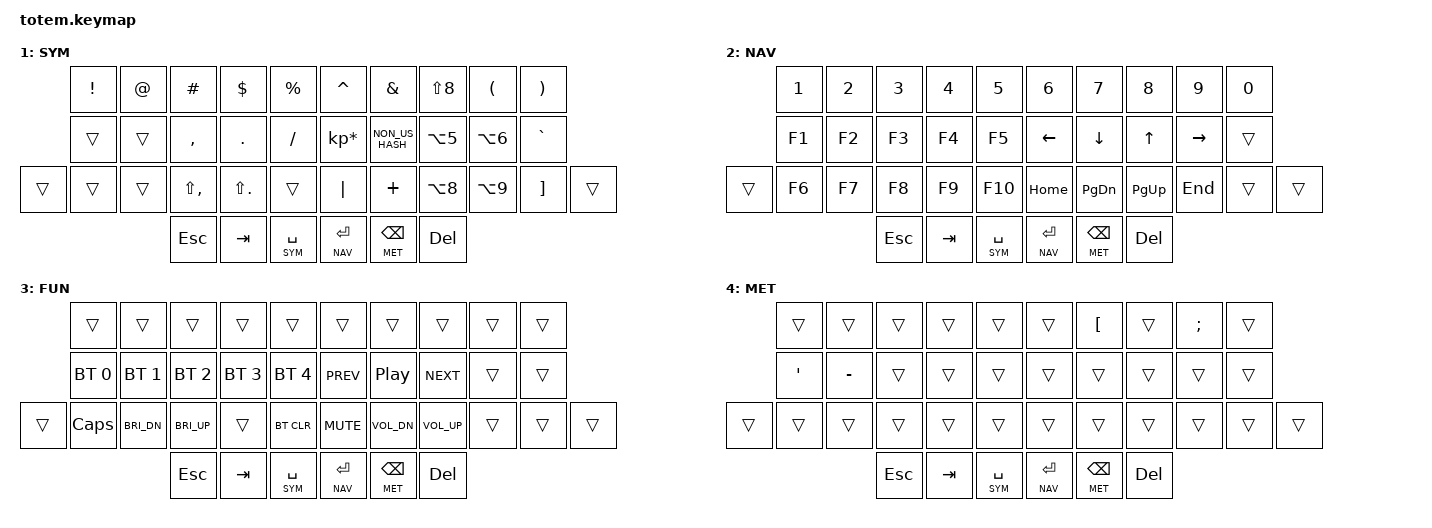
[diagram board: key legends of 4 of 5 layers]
//
//                                                        ▀▀▀▀▀     ▀▀▀▀▀          ▀▀█▀▀
//                                                        ▄▀▀▀▄  ▄  ▄▀▀▀▄  ▄  ▄▀▀▀▄  █  ▄▀▀▀▄
//                                                        █   █  █  █   █  █  █   █  █  █   █
//                                                         ▀▀▀   █   ▀▀▀   █   ▀▀▀   ▀   ▀▀▀
//                                                               █      ▄▄▄█▄▄▄    █   █  
//                                                               ▀      █  █  █     █▄█
//                                                             ▀▀▀▀▀    █  █  █      ▀
//                                                                      ▀  ▀  ▀
//
// ▄▄▄▄▄▄▄▄▄▄▄▄▄▄▄▄▄▄▄▄▄▄▄▄▄▄▄▄▄▄▄▄▄▄▄▄▄▄▄▄▄▄▄▄▄▄▄▄▄▄▄▄▄▄▄▄▄▄▄▄▄▄▄▄▄▄▄▄▄▄▄▄▄▄▄▄▄▄▄▄▄▄▄▄▄▄▄▄▄▄▄▄▄▄▄▄▄▄▄▄▄▄▄▄▄▄▄▄▄▄▄▄▄▄▄▄▄▄▄▄▄▄▄▄▄▄▄▄▄▄▄▄▄▄▄▄▄▄▄▄▄▄▄▄▄▄▄▄▄
       

#include <behaviors.dtsi>
#include <dt-bindings/zmk/keys.h>
#include <dt-bindings/zmk/bt.h>
#include <dt-bindings/zmk/outputs.h>

#define DEF 0
#define SYM 1
#define NAV 2
#define FUN 3
#define MET 4

//&mt {
//  quick-tap-ms = <100>;
//  global-quick-tap;
//  flavor = "tap-preferred";
//  tapping-term-ms = <170>;
//};
&mt {
    flavor = "hold-preferred";
    tapping-term-ms = <150>;
};

&lt {
    flavor = "balanced";
    tapping-term-ms = <150>;
};

/ {
    behaviors {
        am: alpha_mods {
            compatible = "zmk,behavior-hold-tap";
            label = "ALPHA_MT";
            #binding-cells = <2>;
            tapping-term-ms = <200>;
            quick-tap-ms = <150>;
            flavor = "balanced";
            bindings = <&kp>, <&kp>;
        };
        as: alpha_shift {
            compatible = "zmk,behavior-hold-tap";
            label = "ALPHA_SFT";
            #binding-cells = <2>;
            tapping-term-ms = <200>;
            quick-tap-ms = <150>;
            flavor = "balanced";
            bindings = <&kp>, <&kp>;
        };

        // Easy alt-tab with alt+backspace thumb using mod-morphs
        bstab: backspace_tab {
            compatible = "zmk,behavior-mod-morph";
            label = "BSPC_TAB";
            #binding-cells = <0>;
            bindings = <&kp BSPC>, <&kp TAB>;
            mods = <MOD_LALT>;
        };
        lt_bspc: layer_tap_backspace_tab {
            compatible = "zmk,behavior-hold-tap";
            label = "LT_BT";
            #binding-cells = <2>;
            tapping-term-ms = <150>;
            flavor = "balanced";
            bindings = <&mo>, <&bstab>;
        };
    };

    cond_layers {
        compatible = "zmk,conditional-layers";
        // Define FUN layer as tri-state
        func_tristate {
            if-layers = <NAV SYM>;
            then-layer = <FUN>;
        };
    };

    macros {
        ZMK_MACRO(inv_qm,
            wait-ms = <10>;
            tap-ms = <10>;
            bindings
                = <&macro_press &kp LALT>
                , <&macro_tap &kp KP_N1 &kp KP_N6 &kp KP_N8>
                , <&macro_release &kp LALT>;
        )
    };

        keymap {
                compatible = "zmk,keymap";
// ▄▄▄▄▄▄▄▄▄▄▄▄▄▄▄▄▄▄▄▄▄▄▄▄▄▄▄▄▄▄▄▄▄▄▄▄▄▄▄▄▄▄▄▄▄▄▄▄▄▄▄▄▄▄▄▄▄▄▄▄▄▄▄▄▄▄▄▄▄▄▄▄▄▄▄▄▄▄▄▄▄▄▄▄▄▄▄▄▄▄▄▄▄▄▄▄▄▄▄▄▄▄▄▄▄▄▄▄▄▄▄▄▄▄▄▄▄▄▄▄▄▄▄▄▄▄▄▄▄▄▄▄▄▄▄▄▄▄▄▄▄▄▄▄▄▄▄▄▄

                base_layer {
// ┏━━━━━━━━━━━━━━━━━━━━━━━━━━━━━━━━━━━━━━━┓
label= "BASE"                              ;
// ┗━━━━━━━━━━━━━━━━━━━━━━━━━━━━━━━━━━━━━━━┛
//             ┏━━━━━━━━━━━┳━━━━━━━━━━━┳━━━━━━━━━━━┳━━━━━━━━━━━┳━━━━━━━━━━━┓   ┏━━━━━━━━━━━┳━━━━━━━━━━━┳━━━━━━━━━━━┳━━━━━━━━━━━┳━━━━━━━━━━━┓
//             ┃     Q     ┃     W     ┃     F     ┃     P     ┃     G     ┃   ┃     J     ┃     L     ┃     U     ┃     Y     ┃     ;     ┃
//             ┣━━━━━━━━━━━╋━━━━━━━━━━━╋━━━━━━━━━━━╋━━━━━━━━━━━╋━━━━━━━━━━━┫   ┣━━━━━━━━━━━╋━━━━━━━━━━━╋━━━━━━━━━━━╋━━━━━━━━━━━╋━━━━━━━━━━━┫
//             ┃     A     ┃     R     ┃     S     ┃     T     ┃     D     ┃   ┃     H     ┃     N     ┃     E     ┃     I     ┃     O     ┃
// ┏━━━━━━━━━━━╋━━━━━━━━━━━╋━━━━━━━━━━━╋━━━━━━━━━━━╋━━━━━━━━━━━╋━━━━━━━━━━━┫   ┣━━━━━━━━━━━╋━━━━━━━━━━━╋━━━━━━━━━━━╋━━━━━━━━━━━╋━━━━━━━━━━━╋━━━━━━━━━━━┓
// ┃     Q     ┃     Z     ┃     X     ┃     C     ┃     V     ┃     B     ┃   ┃     K     ┃     M     ┃     ,     ┃     .     ┃     /     ┃     \     ┃
// ┗━━━━━━━━━━━┻━━━━━━━━━━━┻━━━━━━━━━━━╋━━━━━━━━━━━╋━━━━━━━━━━━╋━━━━━━━━━━━┫   ┣━━━━━━━━━━━╋━━━━━━━━━━━╋━━━━━━━━━━━╋━━━━━━━━━━━┻━━━━━━━━━━━┻━━━━━━━━━━━┛
//                                     ┃    DEL    ┃    TAB    ┃    SPC    ┃   ┃   ENTER   ┃           ┃   BSPC    ┃
//                                     ┗━━━━━━━━━━━┻━━━━━━━━━━━┻━━━━━━━━━━━┛   ┗━━━━━━━━━━━┻━━━━━━━━━━━┻━━━━━━━━━━━┛
 bindings = <
// ╷           ╷           ╷           ╷           ╷           ╷           ╷   ╷           ╷           ╷           ╷           ╷           ╷           ╷
//                &kp Q       &kp W       &kp F       &kp P       &kp G           &kp J       &kp L       &kp U       &kp Y       &kp SEMI
//                &mt LGUI A  &mt LALT R  &mt LCTRL S &mt LSHFT T &kp D           &kp H       &mt RSHFT N &mt RCTRL E &mt RALT I  &mt RGUI O
//    &kp Q       &kp Z       &kp X       &kp C       &kp V       &kp B           &kp K       &kp M       &kp COMMA   &kp DOT     &kp FSLH    &kp BSLH
//                                        &kp DEL   &lt NAV TAB   &kp SPACE       &kp RET   &lt SYM ESC   &kp BSPC
                &kp Q       &kp W       &kp E       &kp R       &kp T           &kp Y       &kp U       &kp I       &kp O       &kp P
                &am LCTRL A   &am LGUI S    &am LALT D    &as LSHFT F   &kp G             &kp H         &as RSHFT J   &am RALT K   &am RGUI L    &am RCTRL SEMI
    &kp Q       &kp Z       &kp X       &kp C       &kp V       &kp B           &kp N       &kp M       &kp COMMA   &kp DOT     &kp FSLH    &kp BSLH
                                        &kp ESC       &kp TAB       &lt SYM SPACE &lt NAV RET   &lt MET BSPC  &kp DEL
                                        
     &kp SQT        &kp LBKT       &kp SEMI                                           
                        >;
                };

// ▄▄▄▄▄▄▄▄▄▄▄▄▄▄▄▄▄▄▄▄▄▄▄▄▄▄▄▄▄▄▄▄▄▄▄▄▄▄▄▄▄▄▄▄▄▄▄▄▄▄▄▄▄▄▄▄▄▄▄▄▄▄▄▄▄▄▄▄▄▄▄▄▄▄▄▄▄▄▄▄▄▄▄▄▄▄▄▄▄▄▄▄▄▄▄▄▄▄▄▄▄▄▄▄▄▄▄▄▄▄▄▄▄▄▄▄▄▄▄▄▄▄▄▄▄▄▄▄▄▄▄▄▄▄▄▄▄▄▄▄▄▄▄▄▄▄▄▄▄

               symbol_layer {
// -----------------------------------------------------------------------------------------
// |  |  !  |  "  |  §  |  $  |  %  |   |  & |  /  |  (  |  )  |  =  |    |
//    |     |     |     |     |     |   |  * |  #  |  [  |  ]   |  <  |   |
// |  |     |     |     |     |     |   | '  |  `  |  {  |  }   |  +  |  |
//        | ESC | TAB | SYM / SPC  |            | NAV / ENT | MET / BKSP  | DEL |
                    label = "SYM";
                    bindings = <
// ╭─────────────┬─────────────┬─────────────┬─────────────┬─────────────┬─────────────╮   ╭─────────────┬─────────────┬─────────────┬─────────────┬─────────────┬─────────────╮
                &kp EXCL      &kp AT        &kp HASH      &kp DLLR      &kp PRCNT         &kp CARET     &kp AMPS      &kp LS(N8)     &kp LPAR     &kp RPAR       
// ├─────────────┼─────────────┼─────────────┼─────────────┼─────────────┼─────────────┤   ├─────────────┼─────────────┼─────────────┼─────────────┼─────────────┼─────────────┤
           &trans        &trans        &kp COMMA        &kp DOT     &kp FSLH            &kp KP_MULTIPLY &kp NON_US_HASH &kp LA(N5) &kp LA(N6)  &kp GRAVE      
// ├─────────────┼─────────────┼─────────────┼─────────────┼─────────────┼─────────────┤   ├─────────────┼─────────────┼─────────────┼─────────────┼─────────────┼─────────────┤
    &trans      &trans        &trans        &kp LS(COMMA)     &kp LS(DOT)        &trans            &kp PIPE      &kp PLUS      &kp LA(N8)    &kp LA(N9)    &kp RBKT      &trans
// ╰─────────────┴─────────────┴─────────────┼─────────────┼─────────────┼─────────────┤   ├─────────────┼─────────────┼─────────────┼─────────────┴─────────────┴─────────────╯
                                              &kp ESC       &kp TAB       &lt SYM SPACE     &lt NAV RET   &lt MET BSPC  &kp DEL
//                                           ╰─────────────┴─────────────┴─────────────╯   ╰─────────────┴─────────────┴─────────────╯
                      >;
                };

                navigation_layer {
// -----------------------------------------------------------------------------------------
// | |  1  |  2  |  3  |  4  |  5  |   |  6   |  7  | 8   |  9  |  0  |      |
// | | F1  | F2  | F3  | F4  | F5  |   | LFT  | DWN | UP  | RGT |     |      |
// | | F6  | F7  | F8  | F9  | F10 |   | home | PDN | PUP | END |     |      |
//        | ESC | TAB | SYM / SPC  |            | NAV / ENT | MET / BKSP  | DEL |
                    label = "NAV";
                    bindings = <
// ╭─────────────┬─────────────┬─────────────┬─────────────┬─────────────┬─────────────╮   ╭─────────────┬─────────────┬─────────────┬─────────────┬─────────────┬─────────────╮
           &kp N1        &kp N2        &kp N3        &kp N4         &kp N5           &kp N6        &kp N7        &kp N8        &kp N9         &kp N0       
// ├─────────────┼─────────────┼─────────────┼─────────────┼─────────────┼─────────────┤   ├─────────────┼─────────────┼─────────────┼─────────────┼─────────────┼─────────────┤
          &kp F1        &kp F2        &kp F3        &kp F4        &kp F5            &kp LEFT      &kp DOWN      &kp UP        &kp RIGHT     &trans        
// ├─────────────┼─────────────┼─────────────┼─────────────┼─────────────┼─────────────┤   ├─────────────┼─────────────┼─────────────┼─────────────┼─────────────┼─────────────┤
    &trans        &kp F6        &kp F7        &kp F8        &kp F9        &kp F10           &kp HOME      &kp PG_DN     &kp PG_UP     &kp END       &trans        &trans
// ╰─────────────┴─────────────┴─────────────┼─────────────┼─────────────┼─────────────┤   ├─────────────┼─────────────┼─────────────┼─────────────┴─────────────┴─────────────╯
                                              &kp ESC       &kp TAB       &lt SYM SPACE     &lt NAV RET   &lt MET BSPC  &kp DEL
//                                           ╰─────────────┴─────────────┴─────────────╯   ╰─────────────┴─────────────┴─────────────╯
                        >;
                };

                function_layer {
                    label = "FUN";
                    bindings = <
// ╭─────────────┬─────────────┬─────────────┬─────────────┬─────────────┬─────────────╮   ╭─────────────┬─────────────┬─────────────┬─────────────┬─────────────┬─────────────╮
            &trans        &trans        &trans        &trans        &trans             &trans        &trans        &trans       &trans        &trans        
// ├─────────────┼─────────────┼─────────────┼─────────────┼─────────────┼─────────────┤   ├─────────────┼─────────────┼─────────────┼─────────────┼─────────────┼─────────────┤
            &bt BT_SEL 0  &bt BT_SEL 1  &bt BT_SEL 2  &bt BT_SEL 3  &bt BT_SEL 4      &kp C_PREV    &kp C_PP      &kp C_NEXT  &trans        &trans        
// ├─────────────┼─────────────┼─────────────┼─────────────┼─────────────┼─────────────┤   ├─────────────┼─────────────┼─────────────┼─────────────┼─────────────┼─────────────┤
    &trans        &kp CAPS      &kp C_BRI_DN  &kp C_BRI_UP  &trans        &bt BT_CLR        &kp C_MUTE    &kp C_VOL_DN &kp C_VOL_UP        &trans        &trans        &trans
// ╰─────────────┴─────────────┴─────────────┼─────────────┼─────────────┼─────────────┤   ├─────────────┼─────────────┼─────────────┼─────────────┴─────────────┴─────────────╯
                                              &kp ESC       &kp TAB       &lt SYM SPACE     &lt NAV RET   &lt MET BSPC  &kp DEL
//                                           ╰─────────────┴─────────────┴─────────────╯   ╰─────────────┴─────────────┴─────────────╯
                        >;
                };
                metall_layer {
                    label = "MET";
                    bindings = <
// ╭─────────────┬─────────────┬─────────────┬─────────────┬─────────────┬─────────────╮   ╭─────────────┬─────────────┬─────────────┬─────────────┬─────────────┬─────────────╮
            &trans        &trans        &trans        &trans        &trans              &trans        &kp LBKT        &trans        &kp SEMI        &trans        
// ├─────────────┼─────────────┼─────────────┼─────────────┼─────────────┼─────────────┤   ├─────────────┼─────────────┼─────────────┼─────────────┼─────────────┼─────────────┤
            &kp SQT        &kp MINUS     &trans        &trans        &trans              &trans        &trans        &trans        &trans        &trans        
// ├─────────────┼─────────────┼─────────────┼─────────────┼─────────────┼─────────────┤   ├─────────────┼─────────────┼─────────────┼─────────────┼─────────────┼─────────────┤
    &trans        &trans        &trans        &trans        &trans        &trans              &trans        &trans        &trans        &trans        &trans        &trans
// ╰─────────────┴─────────────┴─────────────┼─────────────┼─────────────┼─────────────┤   ├─────────────┼─────────────┼─────────────┼─────────────┴─────────────┴─────────────╯
                                              &kp ESC       &kp TAB       &lt SYM SPACE     &lt NAV RET   &lt MET BSPC  &kp DEL
//                                           ╰─────────────┴─────────────┴─────────────╯   ╰─────────────┴─────────────┴─────────────╯
                        >;
                };
        };
};
